# S32R372 register map
Vendor: Freescale Semiconductor, Inc.; Series: Qorivva; File version: 1.6
Registers are 32-bit, read-write, reset 0x0 unless marked. A register's access mark holds for its fields unless they carry their own. Offsets are from the block's base; [hi:lo] are bit positions; {n}, {i} and the like mark numbered series; 'fields as' and 'values as' point back to an identical list.

## AIPS_1 — AIPS-Lite Bridge
Base 0xF8000000; register names take the prefix AIPS_1_
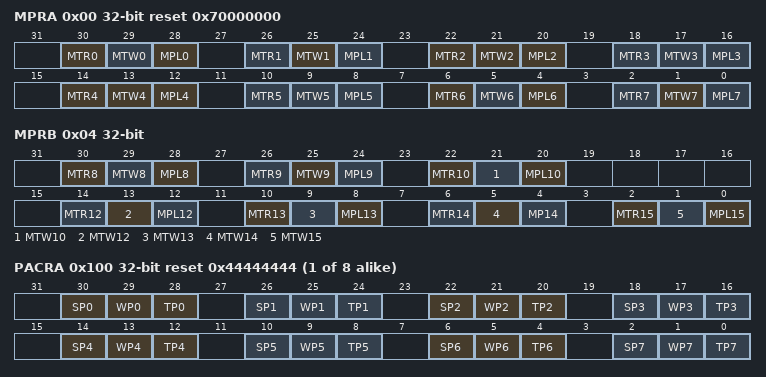
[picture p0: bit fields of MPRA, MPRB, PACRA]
0x00 MPRA reset 0x70000000 — Master Privilege Register A
  [30] MTR0 — Master 0 Trusted For Read
    0=This master is not trusted for read accesses; 1=This master is trusted for read accesses
  [29] MTW0 — Master 0 Trusted For Writes
    0=This master is not trusted for write accesses; 1=This master is trusted for write accesses
  [28] MPL0 — Master 0 Privilege Level
    0=Accesses from this master are forced to user-mode; 1=Accesses from this master are not forced to user-mode
  [26] MTR1 — Master 1 trusted for read
    values as MTR0
  [25] MTW1 — Master 1 trusted for writes
    values as MTW0
  [24] MPL1 — Master 1 privilege level
    values as MPL0
  [30-4n] MTR{n} (n=2..5) — Master {n} Trusted For Read
    values as MTR0
  [29-4n] MTW{n} (n=2..5) — Master {n} Trusted For Writes
    values as MTW0
  [28-4n] MPL{n} (n=2..5) — Master {n} Privilege Level
    values as MPL0
  [6] MTR6 — Master 6 trusted for read
    values as MTR0
  [5] MTW6 — Master 6 trusted for writes
    values as MTW0
  [4] MPL6 — Master 6 privilege level
    values as MPL0
  [2] MTR7 — Master 7 trusted for read
    values as MTR0
  [1] MTW7 — Master 7 trusted for writes
    values as MTW0
  [0] MPL7 — Master 7 privilege level
    values as MPL0
0x04 MPRB — Master Privilege Register B
  [30] MTR8 — Master 8 trusted for read
    values as MPRA.MTR0
  [29] MTW8 — Master 8 trusted for writes
    values as MPRA.MTW0
  [28] MPL8 — Master 8 privilege level
    values as MPRA.MPL0
  [26] MTR9 — Master 9 trusted for read
    values as MPRA.MTR0
  [25] MTW9 — Master 9 trusted for writes
    values as MPRA.MTW0
  [24] MPL9 — Master 9 privilege level
    values as MPRA.MPL0
  [22] MTR10 — Master 10 trusted for read
    values as MPRA.MTR0
  [21] MTW10 — Master 10 trusted for writes
    values as MPRA.MTW0
  [20] MPL10 — Master 10 privilege level
    values as MPRA.MPL0
  [14] MTR12 — Master 12 trusted for read
    values as MPRA.MTR0
  [13] MTW12 — Master 12 trusted for writes
    values as MPRA.MTW0
  [12] MPL12 — Master 12 privilege level
    values as MPRA.MPL0
  [10] MTR13 — Master 13 trusted for read
    values as MPRA.MTR0
  [9] MTW13 — Master 13 trusted for writes
    values as MPRA.MTW0
  [8] MPL13 — Master 13 Privilege Level
    values as MPRA.MPL0
  [6] MTR14 — Master 14 trusted for read
    values as MPRA.MTR0
  [5] MTW14 — Master 14 Trusted For Writes
    values as MPRA.MTW0
  [4] MP14 — Master 14 privilege level
    values as MPRA.MPL0
  [2] MTR15 — Master 15 Trusted For Read
    values as MPRA.MTR0
  [1] MTW15 — Master 15 trusted for writes
    values as MPRA.MTW0
  [0] MPL15 — Master 15 privilege level
    values as MPRA.MPL0
0x100 PACR{x} (x=A,B,C,D,_Reserved,F,G,H; step 0x4) reset 0x44444444 — Peripheral Access Control Register
  [30-4n] SP{n} (n=0..7) — Supervisor Protect
    0=This peripheral does not require supervisor privilege level for accesses; 1=This peripheral requires supervisor privilege level for accesses
  [29-4n] WP{n} (n=0..7) — Write Protect
    0=This peripheral allows write accesses; 1=This peripheral is write protected
  [28-4n] TP{n} (n=0..7) — Trusted Protect
    0=Accesses from an untrusted master are allowed; 1=Accesses from an untrusted master are not allowed
0x140 OPACR{x} (x=A,B,C,D,E,F,G,H,I,J,K,L,M,N,O,P,Q,R,S,T,U,V,W,X,Y,Z,AA,AB,AC,AD,AE,AF; step 0x4) reset 0x44444444 — Off-Platform Peripheral Access Control Register
  fields as PACR{x}

## AIPS_0 — AIPS-Lite Bridge
Base 0xFC000000; register names take the prefix AIPS_0_
Registers as AIPS_1.

## I2C_1 — I2C
Base 0xFBE68000; register names take the prefix I2C_1_
0x00 IBAD 8-bit — I2C Bus Address Register
  [7:1] ADR — Slave Address
0x01 IBFD 8-bit — I2C Bus Frequency Divider Register
  [7:0] IBC — I-Bus Clock Rate
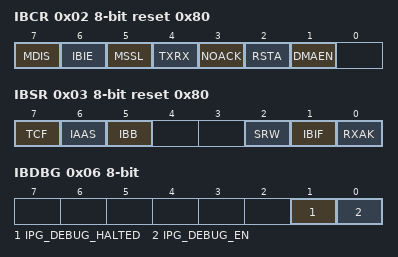
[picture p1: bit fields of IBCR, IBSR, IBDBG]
0x02 IBCR 8-bit reset 0x80 — I2C Bus Control Register
  [7] MDIS — Module disable. This bit controls the software reset of the entire I2C Bus module.
    0=The I2C Bus module is enabled. This bit must be cleared before any other IBCR bits have any effect; 1=The module is reset and disabled. This is the power-on reset situation. When high, the interface is held in reset, but registers can still be accessed. Status register bits (IBSR) are not valid when module is disabled.
  [6] IBIE — I-Bus Interrupt Enable.
    0=Interrupts from the I2C Bus module are disabled. This does not clear any currently pending interrupt condition.; 1=Interrupts from the I2C Bus module are enabled. An I2C Bus interrupt occurs provided the IBIF bit in the status register is also set.
  [5] MSSL — Master/Slave mode select
    0=Slave Mode; 1=Master Mode
  [4] TXRX — Transmit/Receive mode select
    0=Receive; 1=Transmit
  [3] NOACK — Data Acknowledge disable
    0=An acknowledge signal will be sent out to the bus at the 9th clock bit after receiving one byte of data; 1=No acknowledge signal response is sent (i.e., acknowledge bit = 1)
  [2] RSTA wo — Repeat Start
    0=No effect; 1=Generate repeat start cycle
  [1] DMAEN — DMA Enable
    0=Disable the DMA TX/RX request signals; 1=Enable the DMA TX/RX request signals
0x03 IBSR 8-bit reset 0x80 — I2C Bus Status Register
  [7] TCF ro — Transfer complete
    0=Transfer in progress; 1=Transfer complete
  [6] IAAS ro — Addressed as a slave
    0=Not addressed; 1=Addressed as a slave
  [5] IBB ro — Bus busy
    0=Bus is Idle; 1=Bus is busy
  [2] SRW ro — Slave Read/Write
    0=Slave receive, master writing to slave; 1=Slave transmit, master reading from slave
  [1] IBIF — I-Bus Interrupt Flag
  [0] RXAK ro — Received Acknowledge
    0=Acknowledge received; 1=No acknowledge received
0x04 IBDR 8-bit — I2C Bus Data I/O Register
  [7:0] DATA — Data transmitted or received
0x05 IBIC 8-bit — I2C Bus Interrupt Config Register
  [7] BIIE — Bus Idle Interrupt Enable bit
    0=Bus Idle Interrupts disabled; 1=Bus Idle Interrupts enabled
0x06 IBDBG 8-bit — I2C Bus Debug Register
  [1] IPG_DEBUG_HALTED ro — Debug Halted Bit: This is s status bit which can be read back after asserting the debug enable signal so as to know if the IP has entered the debug mode or not
    0=IP is still executing a transaction; 1=IP has entered the debug mode
  [0] IPG_DEBUG_EN — Debug enable bit
    0=Normal operation, Bus Idle Interrupts disabled; 1=IP is in debug mode

## I2C_2 — I2C
Base 0xFBE6C000; register names take the prefix I2C_2_
Registers as I2C_1.
